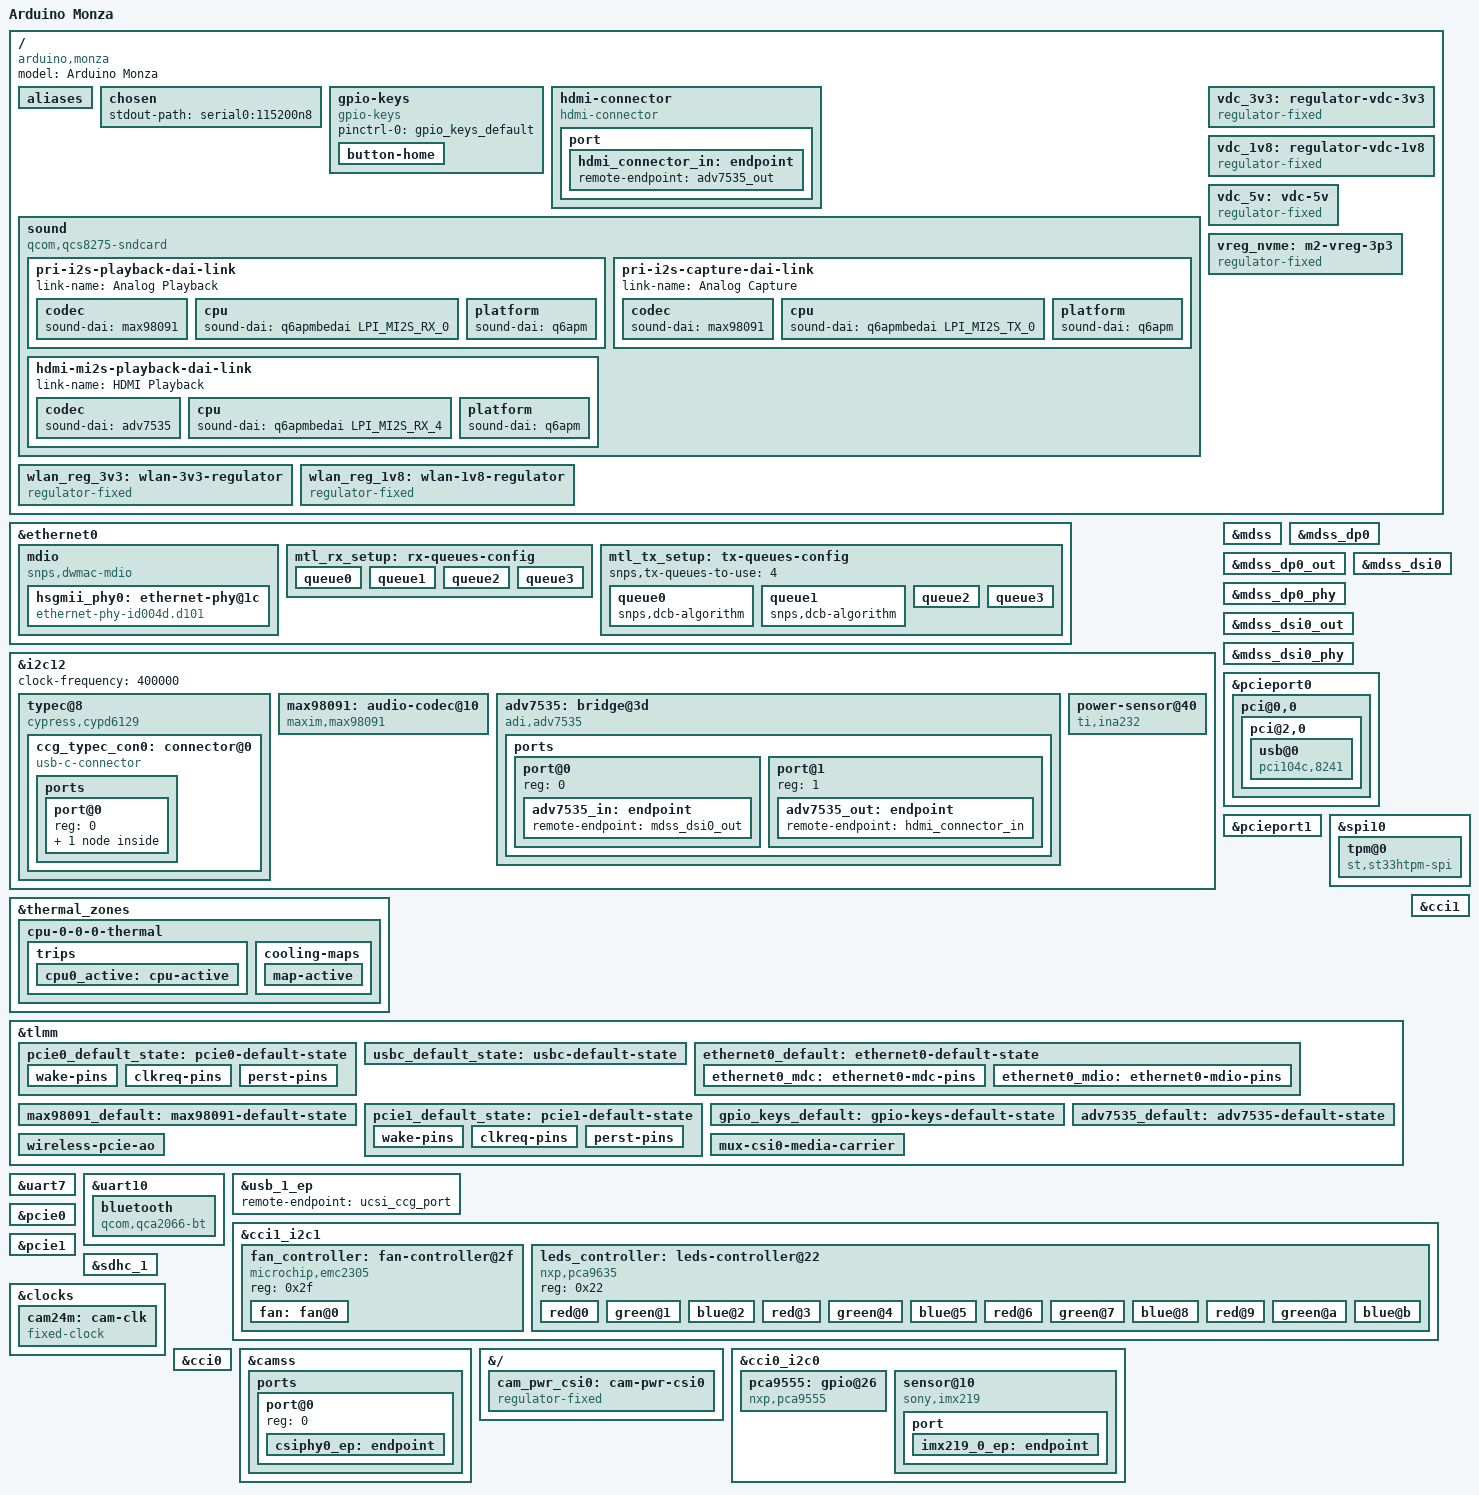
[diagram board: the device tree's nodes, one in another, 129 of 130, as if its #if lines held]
// SPDX-License-Identifier: BSD-3-Clause
/*
 * Copyright (c) Qualcomm Technologies, Inc. and/or its subsidiaries.
 */

/dts-v1/;

#include <dt-bindings/gpio/gpio.h>
#include <dt-bindings/pwm/pwm.h>
#include <dt-bindings/sound/qcom,q6afe.h>
#include <dt-bindings/regulator/qcom,rpmh-regulator.h>
#include <dt-bindings/sound/qcom,q6dsp-lpass-ports.h>

#include "monaco.dtsi"
#include "monaco-pmics.dtsi"
#include "monaco-monza-som.dtsi"

/ {
	model = "Arduino Monza";
	compatible = "arduino,monza", "qcom,qcs8300";

	aliases {
		ethernet0 = &ethernet0;
		i2c1 = &i2c1;
		serial0 = &uart7;
	};

	chosen {
		stdout-path = "serial0:115200n8";
	};

	gpio-keys {
		compatible = "gpio-keys";
		pinctrl-0 = <&gpio_keys_default>;
		pinctrl-names = "default";

		button-home {
			label = "Home Key";
			linux,code = <KEY_HOMEPAGE>;
			gpios = <&tlmm 79 GPIO_ACTIVE_LOW>;
			debounce-interval = <60>;
		};
	};

	hdmi-connector {
		compatible = "hdmi-connector";
		label = "hdmi";
		type = "a";

		port {
			hdmi_connector_in: endpoint {
				remote-endpoint = <&adv7535_out>;
			};
		};
	};

	sound {
		compatible = "qcom,qcs8275-sndcard";
		model = "arduino-monza";
		audio-routing =	
				"IN12",  "Headset Mic12",
				"Headset Mic12",  "MICBIAS",
				"IN56",  "Headset Mic56",
				"Headset Mic56",  "MICBIAS",
				"MIC1",  "MICBIAS",
				"Headphone",  "HPL",
				"Headphone",  "HPR",
				"Receiver",  "RCVL",
				"Receiver",  "RCVR",
				"Speaker",  "SPKL",
				"Speaker",  "SPKR";

		pinctrl-0 = <&quad_mi2s_active>, <&quad_mclk_active>,  <&lpi_i2s4_active>;
		pinctrl-names = "default";

		pri-i2s-playback-dai-link {
			link-name = "Analog Playback";

			codec {
				sound-dai = <&max98091>;
			};

			cpu {
				sound-dai = <&q6apmbedai LPI_MI2S_RX_0>;
			};

			platform {
				sound-dai = <&q6apm>;
			};
		};

		pri-i2s-capture-dai-link {
			link-name = "Analog Capture";

			codec {
				sound-dai = <&max98091>;
			};

			cpu {
				sound-dai = <&q6apmbedai LPI_MI2S_TX_0>;
			};

			platform {
				sound-dai = <&q6apm>;
			};
		};

		hdmi-mi2s-playback-dai-link {
			link-name = "HDMI Playback";

			codec {
				sound-dai = <&adv7535>;
			};

			cpu {
				sound-dai = <&q6apmbedai LPI_MI2S_RX_4>;
			};

			platform {
				sound-dai = <&q6apm>;
			};
		};
	};

	vdc_3v3: regulator-vdc-3v3 {
		compatible = "regulator-fixed";
		regulator-name = "vdc_3v3";
		regulator-min-microvolt = <3300000>;
		regulator-max-microvolt = <3300000>;
	};

	vdc_1v8: regulator-vdc-1v8 {
		compatible = "regulator-fixed";
		regulator-name = "vdc_1v8";
		regulator-min-microvolt = <1800000>;
		regulator-max-microvolt = <1800000>;
	};

	vdc_5v: vdc-5v {
		compatible = "regulator-fixed";
		regulator-name = "vdc_5v";
		regulator-min-microvolt = <5000000>;
		regulator-max-microvolt = <5000000>;
		gpio = <&tlmm 49 GPIO_ACTIVE_HIGH>;
		enable-active-high;
		regulator-always-on;
		startup-delay-us = <20000>;
	};

	vreg_nvme: m2-vreg-3p3 {
		compatible = "regulator-fixed";
		regulator-name = "vreg_m2_3p3";
		regulator-min-microvolt = <3300000>;
		regulator-max-microvolt = <3300000>;
		gpio = <&tlmm 51 GPIO_ACTIVE_HIGH>;
		enable-active-high;
		startup-delay-us = <20000>;
	};

	wlan_reg_3v3: wlan-3v3-regulator {
		compatible = "regulator-fixed";
		regulator-name = "wlan_3v3";
		regulator-min-microvolt = <3300000>;
		regulator-max-microvolt = <3300000>;
		gpio = <&tlmm 54 GPIO_ACTIVE_HIGH>;
		enable-active-high;
		regulator-boot-on;
	};

	wlan_reg_1v8: wlan-1v8-regulator {
		compatible = "regulator-fixed";
		regulator-name = "wlan_1v8";
		regulator-min-microvolt = <1800000>;
		regulator-max-microvolt = <1800000>;
		gpio = <&tlmm 56 GPIO_ACTIVE_HIGH>;
		enable-active-high;
		regulator-boot-on;
	};

};

&ethernet0 {
	phy-mode = "2500base-x"; /* Should be phy-mode = "2500base-x", but cf https://lists.infradead.org/pipermail/linux-arm-kernel/2025-November/1077340.html */
	phy-handle = <&hsgmii_phy0>;

	pinctrl-0 = <&ethernet0_default>;
	pinctrl-names = "default";

	snps,mtl-rx-config = <&mtl_rx_setup>;
	snps,mtl-tx-config = <&mtl_tx_setup>;

	status = "okay";

	mdio {
		compatible = "snps,dwmac-mdio";
		#address-cells = <1>;
		#size-cells = <0>;

		hsgmii_phy0: ethernet-phy@1c {
			compatible = "ethernet-phy-id004d.d101";
			reg = <0x1c>;
			reset-gpios = <&tlmm 50 GPIO_ACTIVE_LOW>;
			reset-assert-us = <11000>;
			reset-deassert-us = <70000>;
		};
	};

	mtl_rx_setup: rx-queues-config {
		snps,rx-queues-to-use = <4>;
		snps,rx-sched-sp;

		queue0 {
			snps,dcb-algorithm;
			snps,map-to-dma-channel = <0x0>;
			snps,route-up;
			snps,priority = <0x1>;
		};

		queue1 {
			snps,dcb-algorithm;
			snps,map-to-dma-channel = <0x1>;
			snps,route-ptp;
		};

		queue2 {
			snps,avb-algorithm;
			snps,map-to-dma-channel = <0x2>;
			snps,route-avcp;
		};

		queue3 {
			snps,avb-algorithm;
			snps,map-to-dma-channel = <0x3>;
			snps,priority = <0xc>;
		};
	};

	mtl_tx_setup: tx-queues-config {
		snps,tx-queues-to-use = <4>;

		queue0 {
			snps,dcb-algorithm;
		};

		queue1 {
			snps,dcb-algorithm;
		};

		queue2 {
			snps,avb-algorithm;
			snps,send_slope = <0x1000>;
			snps,idle_slope = <0x1000>;
			snps,high_credit = <0x3e800>;
			snps,low_credit = <0xffc18000>;
		};

		queue3 {
			snps,avb-algorithm;
			snps,send_slope = <0x1000>;
			snps,idle_slope = <0x1000>;
			snps,high_credit = <0x3e800>;
			snps,low_credit = <0xffc18000>;
		};
	};
};

&i2c12 {
	clock-frequency = <400000>;

	status = "okay";

	typec@8 {
		compatible = "cypress,cypd6129";
		reg = <0x08>;
		pinctrl-0 = <&usbc_default_state>;
		pinctrl-names = "default";
		interrupts-extended = <&tlmm 3 IRQ_TYPE_LEVEL_LOW>;
		#address-cells = <1>;
		#size-cells = <0>;

		ccg_typec_con0: connector@0 {
			compatible = "usb-c-connector";
			reg = <0>;
			label = "USB-C";
			data-role = "dual";
			power-role = "dual";

			ports {
				#address-cells = <1>;
				#size-cells = <0>;

				port@0 {
					reg = <0>;

					ucsi_ccg_port: endpoint {
						remote-endpoint = <&usb_1_ep>;
					};
				};
			};
		};
	};

	max98091: audio-codec@10 {
		compatible = "maxim,max98091";
		reg = <0x10>;
		pinctrl-0 = <&max98091_default>;
		pinctrl-names = "default";
		interrupts-extended = <&tlmm 16 IRQ_TYPE_LEVEL_HIGH>; /* GPIO_16 */
		//FIXME move this clk handling to machine driver.
		clocks = <&q6prmcc LPASS_CLK_ID_MCLK_3 LPASS_CLK_ATTRIBUTE_COUPLE_NO>;
		clock-names = "mclk";
		#sound-dai-cells = <0>;
	};

	adv7535: bridge@3d {
		compatible = "adi,adv7535";
		reg = <0x3d>;
		pinctrl-0 = <&adv7535_default>;
		pinctrl-names = "default";
		interrupts-extended = <&tlmm 93 IRQ_TYPE_EDGE_FALLING>;
		avdd-supply = <&vdc_1v8>;
		dvdd-supply = <&vdc_1v8>;
		pvdd-supply = <&vdc_1v8>;
		a2vdd-supply = <&vdc_1v8>;
		v3p3-supply = <&vdc_3v3>;
		v1p2-supply = <&vdc_1v8>;
		adi,dsi-lanes = <4>;
		#sound-dai-cells = <0>;

		ports {
			#address-cells = <1>;
			#size-cells = <0>;

			port@0 {
				reg = <0>;
				adv7535_in: endpoint {
					remote-endpoint = <&mdss_dsi0_out>;
				};
			};

			port@1 {
				reg = <1>;
				adv7535_out: endpoint {
					remote-endpoint = <&hdmi_connector_in>;
				};
			};
		};
	};

	power-sensor@40 {
		compatible = "ti,ina232";
		reg = <0x40>;
		shunt-resistor = <2000>;
	};
};

&mdss {
	status = "okay";
};

&mdss_dp0 {
	status = "okay";
};

&mdss_dp0_out {
	data-lanes = <0 1 2 3>;
	link-frequencies = /bits/ 64 <1620000000 2700000000 5400000000 8100000000>;

	/* Connected to cypd6129 whith routing of HPD to GPIO94 */
};

&mdss_dp0_phy {
	status = "okay";
};

&mdss_dsi0 {
	status = "okay";
};

&mdss_dsi0_out {
	remote-endpoint = <&adv7535_in>;
	data-lanes = <0 1 2 3>;
};

&mdss_dsi0_phy {
	status = "okay";
};

&pcieport0 {
	reset-gpios = <&tlmm 2 GPIO_ACTIVE_LOW>;
	wake-gpios = <&tlmm 0 GPIO_ACTIVE_HIGH>;

	pci@0,0 {
		#address-cells = <3>;
		#size-cells = <2>;
		device_type = "pci";
		bus-range = <0x01 0xff>;
		ranges;
		reg = <0x010000 0x00 0x00 0x00 0x00>;

		pci@2,0 {
			#address-cells = <3>;
			#size-cells = <2>;
			device_type = "pci";
			bus-range = <0x00 0xff>;
			ranges;
			reg = <0x021000 0x00 0x00 0x00 0x00>;

			usb@0 {
				compatible = "pci104c,8241";
				reg = <0 0 0 0 0>;
				ti,pwron-active-high;
			};
		};
	};
};

&pcieport1 {
	reset-gpios = <&tlmm 23 GPIO_ACTIVE_LOW>;
	wake-gpios = <&tlmm 21 GPIO_ACTIVE_HIGH>;
};

&spi10 {
	status = "okay";

	tpm@0 {
		compatible = "st,st33htpm-spi", "tcg,tpm_tis-spi";
		reg = <0>;
		spi-max-frequency = <20000000>;
	};
};

&thermal_zones {
	cpu-0-0-0-thermal {
		trips {
			cpu0_active: cpu-active {
				temperature = <38000>;
				hysteresis = <3000>;
				type = "active";
			};
		};

		cooling-maps {
			map-active {
				trip = <&cpu0_active>;
				cooling-device = <&fan 4 THERMAL_NO_LIMIT>;
			};
		};
	};
};

&tlmm {
	pcie0_default_state: pcie0-default-state {
		wake-pins {
			pins = "gpio0";
			function = "gpio";
			drive-strength = <2>;
			bias-pull-up;
		};

		clkreq-pins {
			pins = "gpio1";
			function = "pcie0_clkreq";
			drive-strength = <2>;
			bias-pull-up;
		};

		perst-pins {
			pins = "gpio2";
			function = "gpio";
			drive-strength = <2>;
			bias-pull-up;
		};
	};

	usbc_default_state: usbc-default-state {
		pins = "gpio3";
		function = "gpio";
		bias-disable;
	};

       	ethernet0_default: ethernet0-default-state {
		ethernet0_mdc: ethernet0-mdc-pins {
			pins = "gpio5";
			function = "emac0_mdc";
			drive-strength = <16>;
			bias-pull-up;
		};

		ethernet0_mdio: ethernet0-mdio-pins {
			pins = "gpio6";
			function = "emac0_mdio";
			drive-strength = <16>;
			bias-pull-up;
		};
	};

	max98091_default: max98091-default-state {
		pins = "gpio16";
		function = "gpio";
		bias-pull-up;
	};

	pcie1_default_state: pcie1-default-state {
		wake-pins {
			pins = "gpio21";
			function = "gpio";
			drive-strength = <2>;
			bias-pull-up;
		};

		clkreq-pins {
			pins = "gpio22";
			function = "pcie1_clkreq";
			drive-strength = <2>;
			bias-pull-up;
		};

		perst-pins {
			pins = "gpio23";
			function = "gpio";
			drive-strength = <2>;
			bias-pull-up;
		};
	};

	gpio_keys_default: gpio-keys-default-state {
		pins = "gpio79";
		function = "gpio";
		bias-disable;
	};

	adv7535_default: adv7535-default-state {
		pins = "gpio93";
		function = "gpio";
		bias-pull-up;
	};
};

&uart7 {
	status = "okay";
};

&uart10 {
	status = "okay";

	bluetooth: bluetooth {
		compatible = "qcom,qca2066-bt";
		max-speed = <3200000>;
		enable-gpios = <&tlmm 55 GPIO_ACTIVE_HIGH>;

		/* should be linked to pcie-m2-e-connector (when available upstream) */

		status = "okay";
	};
};

&usb_1_ep {
	remote-endpoint = <&ucsi_ccg_port>;
};

&cci1 {
	status = "okay";
};

&cci1_i2c1 {
	#address-cells = <1>;
	#size-cells = <0>;

	fan_controller: fan-controller@2f {
		compatible = "microchip,emc2305";
		reg = <0x2f>;
		#address-cells = <1>;
		#size-cells = <0>;
		#pwm-cells = <3>;

		fan: fan@0 {
			reg = <0x0>;
			pwms = <&fan_controller 26000 PWM_POLARITY_INVERTED 1>;
			#cooling-cells = <2>;
		};
	};

	leds_controller: leds-controller@22 {
		compatible = "nxp,pca9635";
		#address-cells = <1>;
		#size-cells = <0>;
		reg = <0x22>;

		red@0 {
			label = "red";
			reg = <0>;
			linux,default-trigger = "none";
		};
		green@1 {
			label = "green";
			reg = <1>;
			linux,default-trigger = "none";
		};
		blue@2 {
			label = "blue";
			reg = <2>;
			linux,default-trigger = "none";
		};
		red@3 {
			label = "red";
			reg = <3>;
			linux,default-trigger = "none";
		};
		green@4 {
			label = "green";
			reg = <4>;
			linux,default-trigger = "none";
		};
		blue@5 {
			label = "blue";
			reg = <5>;
			linux,default-trigger = "none";
		};
		red@6 {
			label = "red";
			reg = <6>;
			linux,default-trigger = "none";
		};
		green@7 {
			label = "green";
			reg = <7>;
			linux,default-trigger = "none";
		};
		blue@8 {
			label = "blue";
			reg = <8>;
			linux,default-trigger = "none";
		};
		red@9 {
			label = "red";
			reg = <9>;
			linux,default-trigger = "none";
		};
		green@a {
			label = "green";
			reg = <10>;
			linux,default-trigger = "none";
		};
		blue@b {
			label = "blue";
			reg = <11>;
			linux,default-trigger = "none";
		};


};

};

&pcie0 {
	pinctrl-0 = <&pcie0_default_state>;
	pinctrl-names = "default";

	vddpe-3v3-supply = <&vdc_3v3>;
};

&pcie1 {
	pinctrl-0 = <&pcie1_default_state>;
	pinctrl-names = "default";

	vddpe-3v3-supply = <&vreg_nvme>;
};

&sdhc_1 {
	vmmc-supply = <&vreg_l8a>;
	vqmmc-supply = <&vreg_s2s>;

	no-sd;
	no-sdio;
	non-removable;

	status = "okay";
};

&tlmm {
	wireless-pcie-ao {
		gpio-hog;
		gpios = <56 0>;
		output-high;
	};
};

/* Camera TODO: Move to overlay */
&clocks {
        cam24m: cam-clk {
                compatible = "fixed-clock";
                #clock-cells = <0>;
                clock-frequency = <24000000>;
                clock-output-names = "cam24m";
        };
};

/* Select CAMERA here */
#define MONZA_FLAT0
#undef MONZA_FLAT1
#undef MONZA_FLAT2
#undef MONZA_JMEDIA
/**/

#ifdef MONZA_JMEDIA
&cci0 {
	status = "okay";
};

&camss {
	vdda-phy-supply = <&vreg_l4a>;
	vdda-pll-supply = <&vreg_l5a>;

	status = "okay";

	ports {
		#address-cells = <1>;
		#size-cells = <0>;

		port@0 {
			reg = <0>;

			csiphy0_ep: endpoint {
				data-lanes = <0 1>;
				remote-endpoint = <&imx219_0_ep>;
			};
		};
	};

};

&{/} {
	cam_pwr_csi0: cam-pwr-csi0 {
		compatible = "regulator-fixed";
		regulator-name = "cam-pwr";
		startup-delay-us = <100000>;
		gpio = <&pca9555 1 GPIO_ACTIVE_HIGH>;
		enable-active-high;
	};
};

&tlmm {
	mux-csi0-media-carrier {
		gpio-hog;
		gpios = <24 0>;
		output-low;
	};
};

&cci0_i2c0 {
	#address-cells = <1>;
	#size-cells = <0>;

	pca9555: gpio@26 {
		compatible = "nxp,pca9555";
		reg = <0x26>;
		gpio-controller;
		#gpio-cells = <2>;
	};

	sensor@10 {
		compatible = "sony,imx219";
		reg = <0x10>;
		clocks = <&cam24m>;
		status = "okay";

		VDIG-supply = <&cam_pwr_csi0>;
		VANA-supply = <&cam_pwr_csi0>;
		VDDL-supply = <&cam_pwr_csi0>;

		reset-gpios = <&pca9555 0 GPIO_ACTIVE_HIGH>;

		port {
			/* MIPI CSI-2 bus endpoint */
			imx219_0_ep: endpoint {
				remote-endpoint = <&csiphy0_ep>;
				clock-lanes = <0>;
				data-lanes = <1 2>;
				link-frequencies = /bits/ 64 <456000000>;
			};
		};
	};
};
#else
#ifdef MONZA_FLAT0
&cci0 {
	status = "okay";
};

&cci0_i2c0 {
	#address-cells = <1>;
	#size-cells = <0>;

	sensor@10 {
		compatible = "sony,imx219";
		reg = <0x10>;
		clocks = <&cam24m>;
		status = "okay";

		reset-gpios = <&tlmm 64 GPIO_ACTIVE_HIGH>;

		port {
			/* MIPI CSI-2 bus endpoint */
			imx219_0_ep: endpoint {
				remote-endpoint = <&csiphy0_ep>;
				clock-lanes = <0>;
				data-lanes = <1 2>;
				link-frequencies = /bits/ 64 <456000000>;
			};
		};
	};
};
#endif
#ifdef MONZA_FLAT1
&cci1 {
	status = "okay";
};

&cci1_i2c0 {
	#address-cells = <1>;
	#size-cells = <0>;

	sensor@10 {
		compatible = "sony,imx219";
		reg = <0x10>;
		clocks = <&cam24m>;
		status = "okay";

		reset-gpios = <&tlmm 75 GPIO_ACTIVE_HIGH>;

		port {
			/* MIPI CSI-2 bus endpoint */
			imx219_1_ep: endpoint {
				remote-endpoint = <&csiphy1_ep>;
				clock-lanes = <0>;
				data-lanes = <1 2>;
				link-frequencies = /bits/ 64 <456000000>;
			};
		};
	};
};
#endif
#ifdef MONZA_FLAT2
&cci2 {
	status = "okay";
};

&cci2_i2c0 {
	#address-cells = <1>;
	#size-cells = <0>;

	sensor@10 {
		compatible = "sony,imx219";
		reg = <0x10>;
		clocks = <&cam24m>;
		status = "okay";

		reset-gpios = <&tlmm 82 GPIO_ACTIVE_HIGH>;

		port {
			/* MIPI CSI-2 bus endpoint */
			imx219_2_ep: endpoint {
				remote-endpoint = <&csiphy2_ep>;
				clock-lanes = <0>;
				data-lanes = <1 2>;
				link-frequencies = /bits/ 64 <456000000>;
			};
		};
	};
};
#endif

&camss {
	vdda-phy-supply = <&vreg_l4a>;
	vdda-pll-supply = <&vreg_l5a>;

	status = "okay";

	ports {
		#address-cells = <1>;
		#size-cells = <0>;

#ifdef MONZA_FLAT0
		port@0 {
			reg = <0>;

			csiphy0_ep: endpoint {
				data-lanes = <0 1>;
				remote-endpoint = <&imx219_0_ep>;
			};
		};
#endif
#ifdef MONZA_FLAT1
		port@1 {
			reg = <1>;

			csiphy1_ep: endpoint {
				data-lanes = <0 1>;
				remote-endpoint = <&imx219_1_ep>;
			};
		};
#endif
#ifdef MONZA_FLAT2
		port@2 {
			reg = <2>;

			csiphy2_ep: endpoint {
				data-lanes = <0 1>;
				remote-endpoint = <&imx219_2_ep>;
			};
		};
#endif
	};

};
#endif

